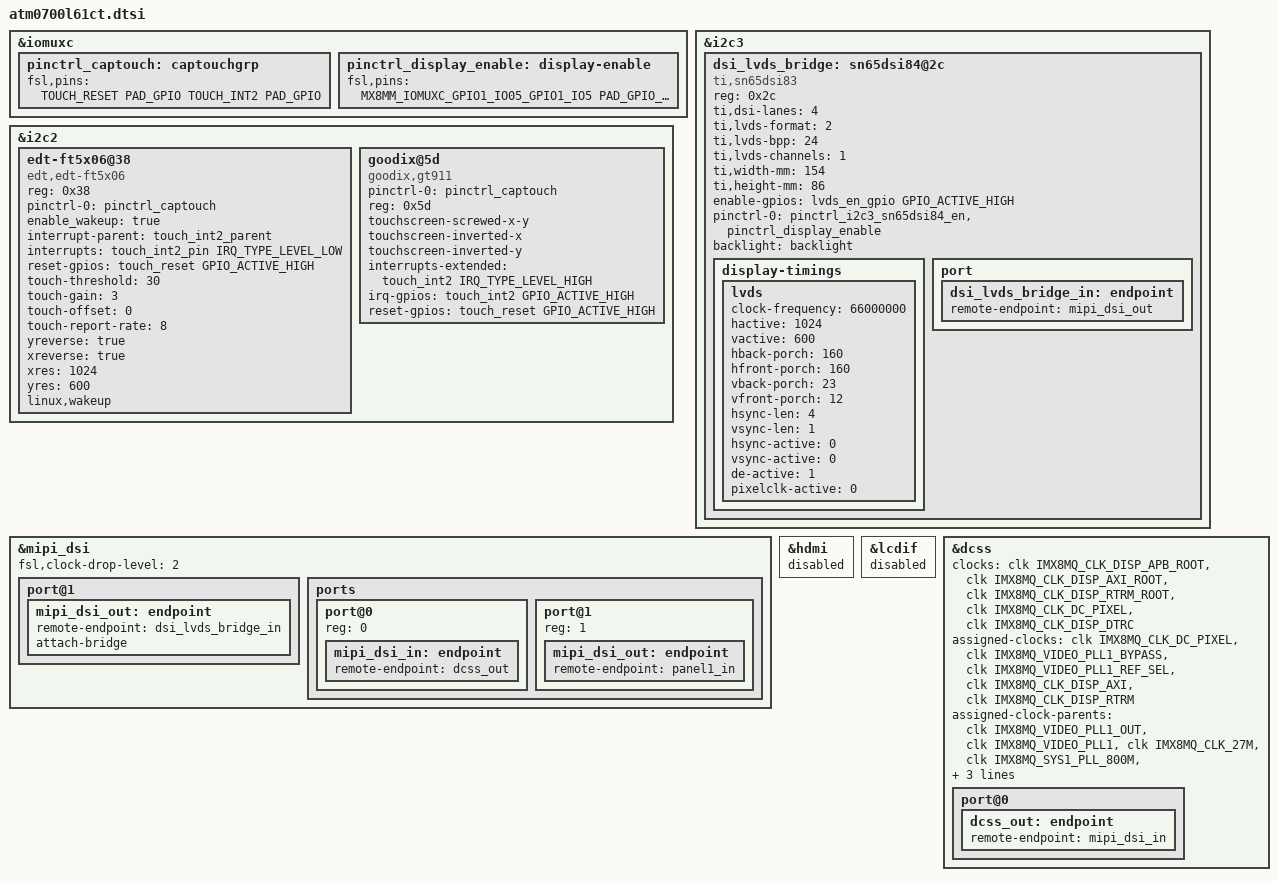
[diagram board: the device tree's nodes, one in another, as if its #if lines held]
/*
 * Copyright 2020 Keith & Koep GmbH
 *
 */

/*
Defines:
    TOUCH_USE_INT2  Set if alternate touch-interrupt should be used.

    TOUCH_INT      Defined in xxx_pinfunc.h. (SODIMM-pin: 45: pConXS)
    TOUCH_INT2     Defined in xxx_pinfunc.h. (SODIMM-pin: 55: i-PANT7, i-PAN T10)
    TOUCH_RESET    Defined in xxx_pinfunc.h. (SODIMM-pin: 75)
*/

&iomuxc {
	pinctrl_captouch: captouchgrp {
		fsl,pins = <                    
					 TOUCH_RESET		PAD_GPIO /* WAKE */
#if defined(TOUCH_USE_INT2) && (TOUCH_USE_INT2==1)
					 TOUCH_INT2 		PAD_GPIO /* IRQ */
#else
					 TOUCH_INT  		PAD_GPIO /* IRQ */
#endif
			   	>;
	};
		
	pinctrl_display_enable: display-enable 	{
#if defined (__DTS_IMX8MM_PINFUNC_H)		
		fsl,pins = <MX8MM_IOMUXC_GPIO1_IO05_GPIO1_IO5	PAD_GPIO_PU>;
#else		
		fsl,pins = < DISPLAY_ENABLE	PAD_GPIO_PU >; /* DISPLAY_ENABLE */
#endif		
	};
};


&i2c2 {
        // Keith & Koep Version
	edt-ft5x06@38 {
		compatible = "edt,edt-ft5x06", "edt,edt-ft5406";
		reg = <0x38>;
		pinctrl-names = "default";
		pinctrl-0 = <&pinctrl_captouch>;
		enable_wakeup = "true";
#if defined(TOUCH_USE_INT2) && (TOUCH_USE_INT2==1)
		interrupt-parent = <touch_int2_parent>;
		interrupts = <touch_int2_pin IRQ_TYPE_LEVEL_LOW>;
#else
		interrupt-parent = <touch_int_parent>;
		interrupts = <touch_int_pin IRQ_TYPE_LEVEL_LOW>;
#endif
		reset-gpios         = <touch_reset GPIO_ACTIVE_HIGH>;
		touch-threshold     = <30>;
		touch-gain          = <3>;
		touch-offset        = <0>;
		touch-report-rate   = <8>;
                yreverse            = "true";
                xreverse            = "true";
 		xres                = <1024>;
 		yres	            = <600>;
		linux,wakeup;
	};
        // AZ Standard Version
	goodix@5d {
		compatible = "goodix,gt911";
		pinctrl-names = "default";
		pinctrl-0 = <&pinctrl_captouch>;
		reg = <0x5d>;

		touchscreen-screwed-x-y;	
		touchscreen-inverted-x;
		touchscreen-inverted-y;
#if defined(TOUCH_USE_INT2) && (TOUCH_USE_INT2==1)
    	        interrupts-extended = <touch_int2 IRQ_TYPE_LEVEL_HIGH>;
		irq-gpios = <touch_int2 GPIO_ACTIVE_HIGH>;
#else
    	        interrupts-extended = <touch_int IRQ_TYPE_LEVEL_HIGH>;
		irq-gpios = <touch_int GPIO_ACTIVE_HIGH>;
#endif
		reset-gpios = <touch_reset GPIO_ACTIVE_HIGH>;
	};
};

&i2c3 {
    dsi_lvds_bridge: sn65dsi84@2c {
		compatible      = "ti,sn65dsi83";
		reg             = <0x2c>;
		ti,dsi-lanes    = <4>;
		ti,lvds-format  = <2>;
		ti,lvds-bpp     = <24>;
		ti,lvds-channels= <1>;
		ti,width-mm     = <154>;
		ti,height-mm    = <86>;
		enable-gpios    = <lvds_en_gpio GPIO_ACTIVE_HIGH>;
		pinctrl-names   = "default";
		pinctrl-0       = <&pinctrl_i2c3_sn65dsi84_en>, <&pinctrl_display_enable>;
		status          = "okay";
		backlight       = <&backlight>;
		display-timings {
			lvds {
				clock-frequency = <66000000>;
				hactive = <1024>;
				vactive = <600>;
				hback-porch = <160>;
				hfront-porch = <160>;
				vback-porch = <23>;
				vfront-porch = <12>;
				hsync-len = <4>;
				vsync-len = <1>;
				hsync-active = <0>;
				vsync-active = <0>;
				de-active = <1>;
				pixelclk-active = <0>;
			};
		};
		port {
			dsi_lvds_bridge_in: endpoint {
				remote-endpoint = <&mipi_dsi_out>;
			};
		};
    };                            
};

&mipi_dsi {
	status  = "okay";
#if defined (__DTS_IMX8MM_PINFUNC_H) || defined (__DTS_IMX8MN_PINFUNC_H)
	port@1 {
		mipi_dsi_out: endpoint {
			remote-endpoint = <&dsi_lvds_bridge_in>;
			attach-bridge;
		};
	};
#endif	
};
/************************************************************************/
#if defined (__DTS_TRIZEPS8_PINFUNC_H)
&hdmi {
	status = "disabled";
};

&lcdif {
	status = "disabled";
};

&dcss {
	status = "okay";

	clocks = <&clk IMX8MQ_CLK_DISP_APB_ROOT>,
		 <&clk IMX8MQ_CLK_DISP_AXI_ROOT>,
		 <&clk IMX8MQ_CLK_DISP_RTRM_ROOT>,
		 <&clk IMX8MQ_CLK_DC_PIXEL>,
		 <&clk IMX8MQ_CLK_DISP_DTRC>;
	clock-names = "apb", "axi", "rtrm", "pix", "dtrc";
	assigned-clocks = <&clk IMX8MQ_CLK_DC_PIXEL>,
					  <&clk IMX8MQ_VIDEO_PLL1_BYPASS>,
					  <&clk IMX8MQ_VIDEO_PLL1_REF_SEL>,
					  <&clk IMX8MQ_CLK_DISP_AXI>,
					  <&clk IMX8MQ_CLK_DISP_RTRM>;
	assigned-clock-parents = <&clk IMX8MQ_VIDEO_PLL1_OUT>,
							 <&clk IMX8MQ_VIDEO_PLL1>,
							 <&clk IMX8MQ_CLK_27M>,
							 <&clk IMX8MQ_SYS1_PLL_800M>,
							 <&clk IMX8MQ_SYS1_PLL_800M>;
	assigned-clock-rates = <600000000>, <0>, <0>,
						   <800000000>,
						   <400000000>;

	port@0 {
		dcss_out: endpoint {
			remote-endpoint = <&mipi_dsi_in>;
		};
	};
};

&mipi_dsi {
    fsl,clock-drop-level = <2>;
	ports {
		#address-cells = <1>;
		#size-cells = <0>;

		port@0 {
			reg = <0>;
			mipi_dsi_in: endpoint {
				remote-endpoint = <&dcss_out>;
			};
		};

		port@1 {
			reg = <1>;
			mipi_dsi_out: endpoint {
				remote-endpoint = <&panel1_in>;
			};
		};
	};
};
#endif
/************************************************************************/
